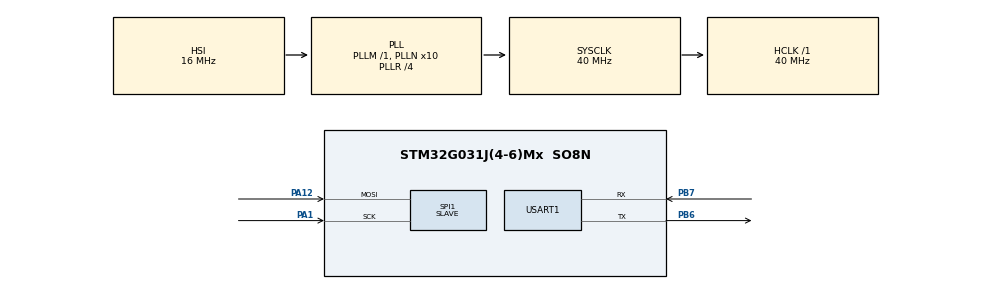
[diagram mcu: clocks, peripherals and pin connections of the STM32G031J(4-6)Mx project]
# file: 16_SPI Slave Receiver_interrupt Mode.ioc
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Mcu.Family=STM32G0
Mcu.Name=STM32G031J(4-6)Mx
Mcu.Package=SO8N
NVIC.SPI1_IRQn=true\:0\:0\:false\:false\:true\:true\:true\:true
PA1.Mode=RX_Only_Simplex_Unidirect_Slave
PA1.Signal=SPI1_SCK
PA12\ [PA10].Mode=RX_Only_Simplex_Unidirect_Slave
PA12\ [PA10].Signal=SPI1_MOSI
PA14-BOOT0__PA15__PB5__PB6.StandardMode=true
PB0__PB1__PA8__PA11\ [PA9].StandardMode=true
PB6.Mode=Asynchronous
PB6.Signal=USART1_TX
PB7.Mode=Asynchronous
PB7.Signal=USART1_RX
PC14-OSC32_IN\ (PC14)__PB7__PB8__PB9.StandardMode=true
PF2\ -\ NRST__PA0__PA1__PA2.StandardMode=true
ProjectManager.HeapSize=0x200
ProjectManager.StackSize=0x400
ProjectManager.TargetToolchain=STM32CubeIDE
RCC.ADCFreq_Value=40000000
RCC.AHBFreq_Value=40000000
RCC.CortexFreq_Value=40000000
RCC.EXTERNAL_CLOCK_VALUE=12288000
RCC.HCLKFreq_Value=40000000
RCC.HSE_VALUE=8000000
RCC.HSI_VALUE=16000000
RCC.LSE_VALUE=32768
RCC.PLLN=10
RCC.PLLR=RCC_PLLR_DIV4
RCC.SYSCLKFreq_VALUE=40000000
RCC.SYSCLKSource=RCC_SYSCLKSOURCE_PLLCLK
RCC.VCOOutputFreq_Value=160000000
SPI1.Direction=SPI_DIRECTION_2LINES_RXONLY
SPI1.Mode=SPI_MODE_SLAVE
SPI1.VirtualType=VM_SLAVE
USART1.VirtualMode-Asynchronous=VM_ASYNC
board=custom

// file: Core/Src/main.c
/* USER CODE BEGIN Header */
/**
  ******************************************************************************
  * @file           : main.c
  * @brief          : Main program body
  ******************************************************************************
  * @attention
  *
  * Copyright (c) 2023 STMicroelectronics.
  * All rights reserved.
  *
  * This software is licensed under terms that can be found in the LICENSE file
  * in the root directory of this software component.
  * If no LICENSE file comes with this software, it is provided AS-IS.
  *
  ******************************************************************************
  */
/* USER CODE END Header */
#include "main.h"

SPI_HandleTypeDef hspi1;

UART_HandleTypeDef huart1;

void SystemClock_Config(void);
static void MX_GPIO_Init(void);
static void MX_SPI1_Init(void);
static void MX_USART1_UART_Init(void);
/* USER CODE BEGIN PFP */
void HAL_SPI_RxCpltCallback(SPI_HandleTypeDef *hspi);
/* USER CODE END PFP */

/* USER CODE BEGIN 0 */
uint8_t RX_buffer[2]={0}; // I want to receive data in form of frame of 2 bytes. Process it (send it to uart) and then receive
//the next 2 bytes and so one. This strategy is chosen to illustrate interrupts triggers at every completion of the received data frame(Rx_buffer).
uint8_t RX_data[13]={0};
int pos=0;
/* USER CODE END 0 */

int main(void)
{

  /* MCU Configuration--------------------------------------------------------*/

  /* Reset of all peripherals, Initializes the Flash interface and the Systick. */
  HAL_Init();

  /* Configure the system clock */
  SystemClock_Config();

  /* Initialize all configured peripherals */
  MX_GPIO_Init();
  MX_SPI1_Init();
  MX_USART1_UART_Init();
  /* USER CODE BEGIN 2 */
  //First reception
  HAL_SPI_Receive_IT(&hspi1, RX_buffer,sizeof(RX_buffer));

  /* USER CODE END 2 */

  /* Infinite loop */
  while (1)
  {

  }
}

void SystemClock_Config(void)
{
  RCC_OscInitTypeDef RCC_OscInitStruct = {0};
  RCC_ClkInitTypeDef RCC_ClkInitStruct = {0};

  /** Configure the main internal regulator output voltage
  */
  HAL_PWREx_ControlVoltageScaling(PWR_REGULATOR_VOLTAGE_SCALE1);

  /** Initializes the RCC Oscillators according to the specified parameters
  * in the RCC_OscInitTypeDef structure.
  */
  RCC_OscInitStruct.OscillatorType = RCC_OSCILLATORTYPE_HSI;
  RCC_OscInitStruct.HSIState = RCC_HSI_ON;
  RCC_OscInitStruct.HSIDiv = RCC_HSI_DIV1;
  RCC_OscInitStruct.HSICalibrationValue = RCC_HSICALIBRATION_DEFAULT;
  RCC_OscInitStruct.PLL.PLLState = RCC_PLL_ON;
  RCC_OscInitStruct.PLL.PLLSource = RCC_PLLSOURCE_HSI;
  RCC_OscInitStruct.PLL.PLLM = RCC_PLLM_DIV1;
  RCC_OscInitStruct.PLL.PLLN = 10;
  RCC_OscInitStruct.PLL.PLLP = RCC_PLLP_DIV2;
  RCC_OscInitStruct.PLL.PLLQ = RCC_PLLQ_DIV2;
  RCC_OscInitStruct.PLL.PLLR = RCC_PLLR_DIV4;
  if (HAL_RCC_OscConfig(&RCC_OscInitStruct) != HAL_OK)
  {
    Error_Handler();
  }

  /** Initializes the CPU, AHB and APB buses clocks
  */
  RCC_ClkInitStruct.ClockType = RCC_CLOCKTYPE_HCLK|RCC_CLOCKTYPE_SYSCLK
                              |RCC_CLOCKTYPE_PCLK1;
  RCC_ClkInitStruct.SYSCLKSource = RCC_SYSCLKSOURCE_PLLCLK;
  RCC_ClkInitStruct.AHBCLKDivider = RCC_SYSCLK_DIV1;
  RCC_ClkInitStruct.APB1CLKDivider = RCC_HCLK_DIV1;

  if (HAL_RCC_ClockConfig(&RCC_ClkInitStruct, FLASH_LATENCY_1) != HAL_OK)
  {
    Error_Handler();
  }
}

static void MX_SPI1_Init(void)
{

  /* SPI1 parameter configuration*/
  hspi1.Instance = SPI1;
  hspi1.Init.Mode = SPI_MODE_SLAVE;
  hspi1.Init.Direction = SPI_DIRECTION_2LINES_RXONLY;
  hspi1.Init.DataSize = SPI_DATASIZE_8BIT;
  hspi1.Init.CLKPolarity = SPI_POLARITY_LOW;
  hspi1.Init.CLKPhase = SPI_PHASE_1EDGE;
  hspi1.Init.NSS = SPI_NSS_SOFT;
  hspi1.Init.FirstBit = SPI_FIRSTBIT_MSB;
  hspi1.Init.TIMode = SPI_TIMODE_DISABLE;
  hspi1.Init.CRCCalculation = SPI_CRCCALCULATION_DISABLE;
  hspi1.Init.CRCPolynomial = 7;
  hspi1.Init.CRCLength = SPI_CRC_LENGTH_DATASIZE;
  hspi1.Init.NSSPMode = SPI_NSS_PULSE_DISABLE;
  if (HAL_SPI_Init(&hspi1) != HAL_OK)
  {
    Error_Handler();
  }

}

static void MX_USART1_UART_Init(void)
{

  huart1.Instance = USART1;
  huart1.Init.BaudRate = 115200;
  huart1.Init.WordLength = UART_WORDLENGTH_8B;
  huart1.Init.StopBits = UART_STOPBITS_1;
  huart1.Init.Parity = UART_PARITY_NONE;
  huart1.Init.Mode = UART_MODE_TX_RX;
  huart1.Init.HwFlowCtl = UART_HWCONTROL_NONE;
  huart1.Init.OverSampling = UART_OVERSAMPLING_16;
  huart1.Init.OneBitSampling = UART_ONE_BIT_SAMPLE_DISABLE;
  huart1.Init.ClockPrescaler = UART_PRESCALER_DIV1;
  huart1.AdvancedInit.AdvFeatureInit = UART_ADVFEATURE_NO_INIT;
  if (HAL_UART_Init(&huart1) != HAL_OK)
  {
    Error_Handler();
  }
  if (HAL_UARTEx_SetTxFifoThreshold(&huart1, UART_TXFIFO_THRESHOLD_1_8) != HAL_OK)
  {
    Error_Handler();
  }
  if (HAL_UARTEx_SetRxFifoThreshold(&huart1, UART_RXFIFO_THRESHOLD_1_8) != HAL_OK)
  {
    Error_Handler();
  }
  if (HAL_UARTEx_DisableFifoMode(&huart1) != HAL_OK)
  {
    Error_Handler();
  }

}

static void MX_GPIO_Init(void)
{

  /* GPIO Ports Clock Enable */
  __HAL_RCC_GPIOB_CLK_ENABLE();
  __HAL_RCC_GPIOA_CLK_ENABLE();

}

/* USER CODE BEGIN 4 */

//The routine in the Callback function will be repeated at each 2 bytes frame.
void HAL_SPI_RxCpltCallback(SPI_HandleTypeDef *hspi){
	//Move the received data to a buffer with the same size as the transmitted data "Hello world !"(13)
	RX_data[pos]=RX_buffer[0];
	RX_data[pos+1]=RX_buffer[1];
	pos+=2;
	//Send the data to the UART port of the PC in order to monitor the message in the Realterm console
	HAL_UART_Transmit(&huart1, RX_buffer, sizeof(RX_buffer), 1);
	//Clear RX_buffer to receive the next frame.
	RX_buffer[0]=0;
	RX_buffer[1]=0;
	//One the first reception is done we move to the second one and repeat the process above and so one for the rest of the data.
	HAL_SPI_Receive_IT(&hspi1, RX_buffer, sizeof(RX_buffer));//This line will move the program to the clpt function again.
}

/* USER CODE END 4 */

void Error_Handler(void)
{
  __disable_irq();
  while (1)
  {
  }
}
